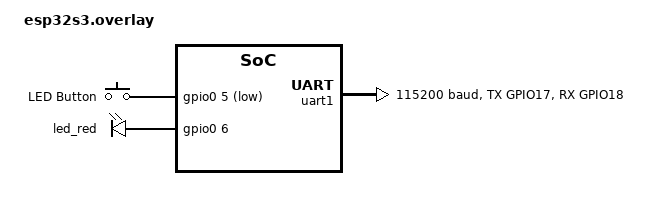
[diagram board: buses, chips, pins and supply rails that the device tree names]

/{
    aliases{
        led-red = &led_red;
        button-led = &button_led;
    };

    buttons {
		compatible = "gpio-keys";
        polling-mode;

        button_led: gpio5 {
            gpios = <&gpio0 5 (GPIO_PULL_UP | GPIO_ACTIVE_LOW)>;
			label = "LED Button";
        };
    };

    leds {
        compatible = "gpio-leds";

        led_red: gpio6 {
          gpios = <&gpio0 6 GPIO_ACTIVE_HIGH>;
        };
    };
    
};

&uart1 {
    status = "okay";
    current-speed = <115200>;

    pinctrl-0 = <&uart1_default>;
    pinctrl-names = "default";
};


&pinctrl {
    uart1_default: uart1_default {
        group1 {
            pinmux = <UART1_TX_GPIO17>;
            output-high;
        };

        group2 {
            pinmux = <UART1_RX_GPIO18>;
            bias-pull-up;
        };
    };
};
